AUTOSAR XML (schema 00051)
package /Components
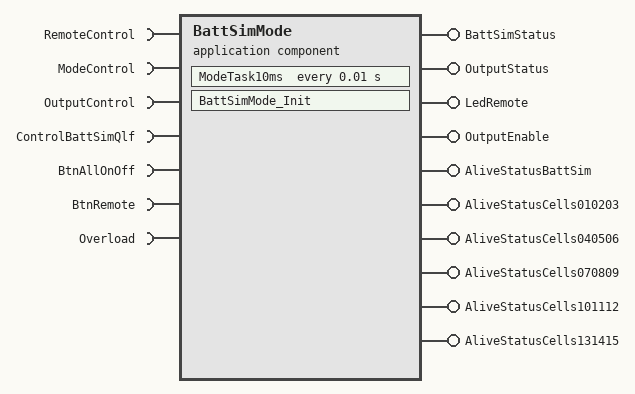
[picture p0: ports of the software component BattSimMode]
  application sw component type BattSimMode
    7 x require port:
      RemoteControl: nonqueued-receiver-com-spec{data-element=RemoteControl, init-value=0}, required-interface=RemoteControl
      ModeControl: nonqueued-receiver-com-spec{data-element=ModeControl, init-value=0}, required-interface=ModeControl
      OutputControl: nonqueued-receiver-com-spec{data-element=OutputControl, init-value=0}, required-interface=OutputControl
      ControlBattSimQlf: nonqueued-receiver-com-spec{data-element=ControlBattSimQlf, init-value=0}, required-interface=ControlBattSimQlf
      BtnAllOnOff: nonqueued-receiver-com-spec{data-element=BtnAllOnOff, init-value=0}, required-interface=BtnAllOnOff
      BtnRemote: nonqueued-receiver-com-spec{data-element=BtnRemote, init-value=0}, required-interface=BtnRemote
      Overload: nonqueued-receiver-com-spec{data-element=Overload, init-value=0}, required-interface=Overload
    10 x provide port:
      BattSimStatus: nonqueued-sender-com-spec{data-element=BattSimStatus, init-value=0}, provided-interface=BattSimStatus
      OutputStatus: nonqueued-sender-com-spec{data-element=OutputStatus, init-value=0}, provided-interface=OutputStatus
      LedRemote: nonqueued-sender-com-spec{data-element=LedRemote, init-value=0}, provided-interface=LedRemote
      OutputEnable: nonqueued-sender-com-spec{data-element=OutputEnable, init-value=0}, provided-interface=OutputEnable
      AliveStatusBattSim: nonqueued-sender-com-spec{data-element=AliveStatusBattSim, init-value=0}, provided-interface=AliveStatusBattSim
      AliveStatusCells010203: nonqueued-sender-com-spec{data-element=AliveStatusCells010203, init-value=0}, provided-interface=AliveStatusCells010203
      AliveStatusCells040506: nonqueued-sender-com-spec{data-element=AliveStatusCells040506, init-value=0}, provided-interface=AliveStatusCells040506
      AliveStatusCells070809: nonqueued-sender-com-spec{data-element=AliveStatusCells070809, init-value=0}, provided-interface=AliveStatusCells070809
      AliveStatusCells101112: nonqueued-sender-com-spec{data-element=AliveStatusCells101112, init-value=0}, provided-interface=AliveStatusCells101112
      AliveStatusCells131415: nonqueued-sender-com-spec{data-element=AliveStatusCells131415, init-value=0}, provided-interface=AliveStatusCells131415
    behavior BattSimMode_IB: handle-termination-and-restart=NO-SUPPORT
      timing event Event_ModeTask10ms: start-on-event=ModeTask10ms, period=0.01
      runnable BattSimMode_Init
      runnable ModeTask10ms
        data-send-points:
          10 x access:
            OUT_BattSimStatus_BattSimStatus: accessed-variable=BattSimStatus.BattSimStatus
            OUT_OutputStatus_OutputStatus: accessed-variable=OutputStatus.OutputStatus
            OUT_LedRemote_LedRemote: accessed-variable=LedRemote.LedRemote
            OUT_OutputEnable_OutputEnable: accessed-variable=OutputEnable.OutputEnable
            OUT_AliveStatusBattSim_AliveStatusBattSim: accessed-variable=AliveStatusBattSim.AliveStatusBattSim
            OUT_AliveStatusCells010203_AliveStatusCells010203: accessed-variable=AliveStatusCells010203.AliveStatusCells010203
            OUT_AliveStatusCells040506_AliveStatusCells040506: accessed-variable=AliveStatusCells040506.AliveStatusCells040506
            OUT_AliveStatusCells070809_AliveStatusCells070809: accessed-variable=AliveStatusCells070809.AliveStatusCells070809
            OUT_AliveStatusCells101112_AliveStatusCells101112: accessed-variable=AliveStatusCells101112.AliveStatusCells101112
            OUT_AliveStatusCells131415_AliveStatusCells131415: accessed-variable=AliveStatusCells131415.AliveStatusCells131415
